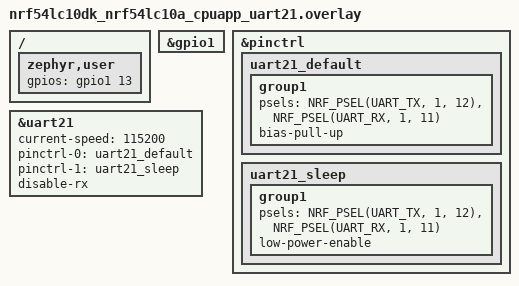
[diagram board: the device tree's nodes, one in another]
/*
 * Copyright (c) 2026 Nordic Semiconductor ASA
 *
 * SPDX-License-Identifier: LicenseRef-Nordic-5-Clause
 */

/*
 * Test requires wire connection between:
 *  - uart21 TX at P1.12 <-> GPIO input at P1.13
 */

/ {
	zephyr,user {
		gpios = <&gpio1 13 GPIO_ACTIVE_HIGH>;
	};
};

&gpio1 {
	status = "okay";
};

&pinctrl {
	uart21_default: uart21_default {
		group1 {
			psels = <NRF_PSEL(UART_TX, 1, 12)>,
				<NRF_PSEL(UART_RX, 1, 11)>;
			bias-pull-up;
		};
	};

	uart21_sleep: uart21_sleep {
		group1 {
			psels = <NRF_PSEL(UART_TX, 1, 12)>,
				<NRF_PSEL(UART_RX, 1, 11)>;
			low-power-enable;
		};
	};
};

dut: &uart21 {
	status = "okay";
	current-speed = <115200>;
	pinctrl-0 = <&uart21_default>;
	pinctrl-1 = <&uart21_sleep>;
	pinctrl-names = "default", "sleep";
	disable-rx;
};
